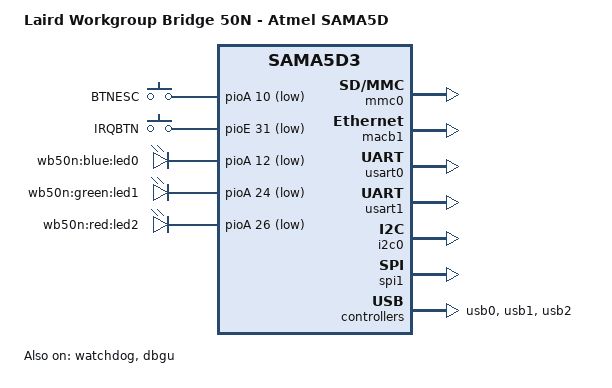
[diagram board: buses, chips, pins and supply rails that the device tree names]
/dts-v1/;
#include "at91-wb50n.dtsi"
/ {
	model = "Laird Workgroup Bridge 50N - Atmel SAMA5D";
	compatible = "laird,wb50n", "atmel,sama5d31", "atmel,sama5d3", "atmel,sama5";
	gpio-keys {
		compatible = "gpio-keys";
		button-0 {
			label = "BTNESC";
			linux,code = <1>;  
			gpios = <&pioA 10 GPIO_ACTIVE_LOW>;
			wakeup-source;
		};
		button-1 {
			label = "IRQBTN";
			linux,code = <99>;  
			gpios = <&pioE 31 GPIO_ACTIVE_LOW>;
			wakeup-source;
		};
	};
	leds {
		compatible = "gpio-leds";
		led0 {
			label = "wb50n:blue:led0";
			gpios = <&pioA 12 GPIO_ACTIVE_LOW>;
			default-state = "off";
		};
		led1 {
			label = "wb50n:green:led1";
			gpios = <&pioA 24 GPIO_ACTIVE_LOW>;
			default-state = "off";
		};
		led2 {
			label = "wb50n:red:led2";
			gpios = <&pioA 26 GPIO_ACTIVE_LOW>;
			default-state = "off";
		};
	};
};
&watchdog {
	status = "okay";
};
&mmc0 {
	status = "okay";
};
&macb1 {
	status = "okay";
};
&dbgu {
	status = "okay";
};
&usart0 {
	status = "okay";
};
&usart1 {
	status = "okay";
};
&i2c0 {
	status = "okay";
};
&spi1 {
	status = "okay";
};
&usb0 {
	status = "okay";
};
&usb1 {
	status = "okay";
};
&usb2 {
	status = "okay";
};
